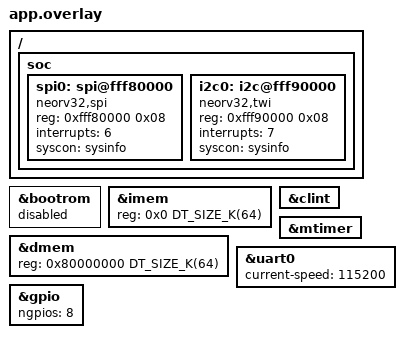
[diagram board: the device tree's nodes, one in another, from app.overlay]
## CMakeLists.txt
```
# Copyright (c) 2026
# SPDX-License-Identifier: GPL-3.0-or-later OR LicenseRef-Ostomachion-Commercial-1.0

cmake_minimum_required(VERSION 3.20.0)

list(APPEND ZEPHYR_EXTRA_MODULES ${CMAKE_CURRENT_SOURCE_DIR})

find_package(Zephyr REQUIRED HINTS $ENV{ZEPHYR_BASE})
project(ostomachion VERSION 0.1.0 LANGUAGES C CXX ASM)

target_include_directories(app PRIVATE include)

target_compile_options(app PRIVATE -Werror)

target_sources(app PRIVATE src/main.cpp)

# ZTest suites — only compiled when ZTEST is enabled
if(CONFIG_ZTEST)
  target_sources(app PRIVATE
    tests/test_spi.cpp
    tests/test_i2c.cpp
    tests/test_gpio.cpp
    # Hardware-independent filter-mask math: runs on the NEORV32 sim model.
    tests/test_filter_mask.cpp
  )
  if(CONFIG_WDT_NEORV32)
    target_sources(app PRIVATE tests/test_wdt.cpp)
  endif()
  if(CONFIG_FFT_ACCEL)
    target_sources(app PRIVATE tests/test_fft_accel.cpp)
  endif()
endif()

if(CONFIG_SHELL)
  target_sources(app PRIVATE src/test_runner.c)
  if(CONFIG_FFT_ACCEL)
    target_sources(app PRIVATE src/fft_shell.c)
  endif()
endif()

if(CONFIG_FFT_DEMO)
  target_sources(app PRIVATE src/fft_demo_main.c)
endif()
```

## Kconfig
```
# Ostomachion application-level Kconfig
# Copyright (c) 2026  SPDX-License-Identifier: GPL-3.0-or-later OR LicenseRef-Ostomachion-Commercial-1.0

menu "Ostomachion application"

config FFT_DEMO
	bool "Build the FFT accelerator host-pipe demo firmware"
	depends on FFT_ACCEL
	default n
	help
	  Enables compilation of src/fft_demo_main.c, which runs a dedicated
	  thread that drives the FFT accelerator from host-provided sample
	  frames carried over the FrontPanel BTPipe endpoints implemented by
	  fp_fft_pipe_bridge.vhd in xem7310_top.vhd.

	  The thread polls the bridge FIFO_IN at 0x90000000 for a full
	  4096-sample frame, runs fft_accel_transform(), and pushes the
	  result back through FIFO_OUT.  The HW cycle count is published
	  via the bridge's REG_PUBLISH register so the host PyQt demo
	  (tools/fft_demo/) can display the speed-up statistic.

	  This config has no effect unless the bitstream was built with the
	  fp_fft_pipe_bridge present (region 0x9000_0000 must respond to
	  XBUS accesses).

endmenu

source "Kconfig.zephyr"
```

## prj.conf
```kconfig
# Core Kernel Features
CONFIG_SERIAL=y
CONFIG_CONSOLE=y
CONFIG_UART_CONSOLE=y
CONFIG_UART_INTERRUPT_DRIVEN=n
CONFIG_GPIO=y
CONFIG_SPI=y
CONFIG_SPI_NEORV32=y
CONFIG_I2C=y
CONFIG_I2C_NEORV32=y

# Modern C++ Support
CONFIG_CPP=y
CONFIG_STD_CPP20=y
CONFIG_PICOLIBC=y

# NOTE: CONFIG_ZTEST is intentionally NOT set here.  prj.conf is the clean
# base/production config; the ZTEST framework is opt-in per build:
#   - GHDL sim test       : added by the `zephyr` Makefile target
#   - Twister / HW tests  : added via testcase.yaml extra_configs
# This keeps the CI firmware-analysis build (CONF_FILE=prj.conf) a real
# production image rather than a test build pulling in all tests/*.cpp.

# I2C slave address for the GHDL testbench slave model (0x50 = 80).
# Set to 0 to skip slave tests.
CONFIG_TEST_I2C_SLAVE_ADDR=80
```

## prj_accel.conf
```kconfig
# prj_accel.conf — Kconfig fragment for the automated ZTEST accelerator build
# Copyright (c) 2026  SPDX-License-Identifier: GPL-3.0-or-later OR LicenseRef-Ostomachion-Commercial-1.0
#
# Stacked on: prj.conf + prj_fpga.conf + prj_hw_test.conf
# Build mode: Automated / CI ZTEST accelerator build.
#
# This fragment only adds the FFT accelerator driver.  CONFIG_ZTEST is NOT set
# in prj.conf (the clean production base); it is supplied by the invoking layer
# — testcase.yaml extra_configs (CONFIG_ZTEST=y) for Twister/HW, or the
# `make test-accel-hw` target.  Verbose ZTEST output comes from prj_hw_test.conf.

CONFIG_FFT_ACCEL=y
CONFIG_FFT_ACCEL_LOG_LEVEL_INF=y
```

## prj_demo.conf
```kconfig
# prj_demo.conf — Kconfig fragment for the host-driven FFT demo firmware
# Copyright (c) 2026  SPDX-License-Identifier: GPL-3.0-or-later OR LicenseRef-Ostomachion-Commercial-1.0
#
# Stacked on: prj.conf + prj_fpga.conf + prj_accel.conf
# Build mode: standalone demo loop (no ZTEST, no Zephyr shell)
#
# Used by: `make demo-hw`.  Drives the FFT accelerator from sample frames
# pushed across the FrontPanel BTPipe endpoints 0x81 / 0xA1 (the host-side
# entry point lives in tools/fft_demo/).

# --- Disable ZTEST (the default base prj.conf enables it) ---
# CONFIG_ZTEST is not set

# --- Enable the application-level FFT demo thread ---
CONFIG_FFT_DEMO=y

# --- Larger stack for the demo thread + FFT transform ---
CONFIG_MAIN_STACK_SIZE=4096

# --- FPU on, matching prj_shell.conf (cosf in test helpers, future use) ---
CONFIG_FPU=y

# --- Logging surface (deferred so the LED-blink thread keeps the WDT fed) ---
CONFIG_LOG=y
CONFIG_LOG_MODE_DEFERRED=y
```

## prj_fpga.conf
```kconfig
# Ostomachion — FPGA (XEM7310-A200) Kconfig fragment
#
# Applied on top of prj.conf when building the FPGA firmware target.
# Increases stack sizes to suit a real RTOS workload and enables the
# interrupt-driven SPI/I2C driver paths (polling is retained in prj.conf
# for simulation convenience).

# Larger stacks for FPGA with real workloads
CONFIG_MAIN_STACK_SIZE=4096
CONFIG_SYSTEM_WORKQUEUE_STACK_SIZE=2048

# Interrupt-driven drivers — production hardware path
# (DTS nodes in app.overlay already declare the correct IRQ numbers;
# this just selects the IRQ code path inside the driver.)
CONFIG_SPI_NEORV32_INTERRUPT=y
CONFIG_I2C_NEORV32_INTERRUPT=y

# Watchdog — hardware WDT enabled (IO_WDT_EN=true in xem7310_top.vhd).
# The application feeds it every 500 ms in the LED blink thread.
# Default timeout: 5000 ms (5 s).  Increase if workloads block longer.
CONFIG_WATCHDOG=y
CONFIG_WDT_NEORV32=y
```

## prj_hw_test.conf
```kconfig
# Hardware test configuration overlay.
#
# Applied on top of prj.conf + prj_fpga.conf for hardware test builds:
#   make test-hw
#
# Enables verbose ztest output and per-subsystem logging so results can be
# read from the UART console at 115200 baud.
#
# CONFIG_TEST_I2C_SLAVE_ADDR=0 means the slave-dependent I2C tests are skipped
# gracefully.  Set to the 7-bit address of any attached I2C device to enable
# those tests (e.g. CONFIG_TEST_I2C_SLAVE_ADDR=80 for a device at 0x50).

# Zephyr logging subsystem
CONFIG_LOG=y
CONFIG_LOG_DEFAULT_LEVEL=3

# Per-driver log levels (INFO = level 3)
CONFIG_SPI_LOG_LEVEL_INF=y
CONFIG_I2C_LOG_LEVEL_INF=y
CONFIG_GPIO_LOG_LEVEL_INF=y

# Verbose ztest output — prints each test name and PASS/FAIL clearly
CONFIG_ZTEST_VERBOSE_OUTPUT=y

# Run the full I2C bus scan (111 probes, ~50 ms) — hardware only.
# Disabled by default to keep GHDL simulation within its 400 ms window.
CONFIG_TEST_I2C_BUS_SCAN=y

# Run the full 64-iteration SPI stress test — hardware only.
# Default (16) fits within the GHDL 400 ms window at ~1 ms/transfer.
CONFIG_TEST_SPI_STRESS_COUNT=64

# No I2C slave attached by default; override on the command line or in a
# per-board fragment if a slave device is present.
CONFIG_TEST_I2C_SLAVE_ADDR=0
```

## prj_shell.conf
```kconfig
# prj_shell.conf — Kconfig fragment for the interactive shell build
# Copyright (c) 2026  SPDX-License-Identifier: GPL-3.0-or-later OR LicenseRef-Ostomachion-Commercial-1.0
#
# Stacked on: prj.conf + prj_fpga.conf
# Build mode: Interactive / Development
#
# CONFIG_ZTEST is explicitly NOT set — the shell owns the UART terminal.
# The LED blink thread and shell thread run indefinitely after boot.

# --- Disable ZTEST (overrides any default) ---
# CONFIG_ZTEST is not set

# --- Zephyr shell ---
CONFIG_SHELL=y
CONFIG_SHELL_BACKEND_SERIAL=y
CONFIG_SHELL_CMD_BUFF_SIZE=128
CONFIG_SHELL_STACK_SIZE=2048
CONFIG_SHELL_LOG_BACKEND=y

# --- FFT accelerator driver ---
CONFIG_FFT_ACCEL=y

# --- Logging over shell ---
CONFIG_LOG=y
CONFIG_LOG_MODE_DEFERRED=y

# --- C++ support for fft_accel.hpp ---
CONFIG_CPP=y
CONFIG_STD_CPP20=y
CONFIG_FPU=y

# --- Larger stacks for shell + FFT workloads ---
CONFIG_MAIN_STACK_SIZE=4096
```

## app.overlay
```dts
#include <zephyr/dt-bindings/dt-util.h>

&bootrom {
	status = "disabled";
};

&imem {
	status = "okay";
	reg = <0x0 DT_SIZE_K(64)>;
};

&dmem {
	status = "okay";
	reg = <0x80000000 DT_SIZE_K(64)>;
};

&clint {
	status = "okay";
};

&mtimer {
	status = "okay";
};

&uart0 {
	status = "okay";
	current-speed = <115200>;
};

&gpio {
	status = "okay";
	ngpios = <8>;
};

/ {
	soc {
		spi0: spi@fff80000 {
			compatible = "neorv32,spi";
			reg = <0xfff80000 0x08>; /* two 32-bit registers: CTRL + DATA */
			status = "okay";
			interrupts = <6>;
			syscon = <&sysinfo>;
			#address-cells = <1>;
			#size-cells = <0>;
		};

		i2c0: i2c@fff90000 {
			compatible = "neorv32,twi";
			reg = <0xfff90000 0x08>; /* two 32-bit registers: CTRL + DCMD */
			status = "okay";
			interrupts = <7>;
			syscon = <&sysinfo>;
			#address-cells = <1>;
			#size-cells = <0>;
		};
	};
};
```

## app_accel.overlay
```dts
/* SPDX-License-Identifier: GPL-3.0-or-later OR LicenseRef-Ostomachion-Commercial-1.0 */
#include <zephyr/dt-bindings/dt-util.h>

/*
 * app_accel.overlay — DTS overlay for the AXI FFT accelerator pipeline
 * Copyright (c) 2026  SPDX-License-Identifier: GPL-3.0-or-later OR LicenseRef-Ostomachion-Commercial-1.0
 *
 * Applied in addition to app.overlay and app_fpga.overlay when building
 * the accelerator firmware (prj_accel.conf or prj_shell.conf).
 *
 * Address map (XBUS region 0x40000000–0x4FFFFFFF):
 *   0x40000000  AXI DMA control registers   128 B   (AXI4-Lite)
 *   0x40010000  AXI INTC                    128 B   (AXI4-Lite)
 *   0x40020000  AXI GPIO (xfft reset)       128 B   (AXI4-Lite)
 *   0x41000000  TX BRAM                      32 KB  (AXI4-Full)
 *   0x41008000  RX BRAM                      32 KB  (AXI4-Full)
 *
 * The FFT core is the Xilinx xfft IP instantiated in the block design.
 * It has no AXI4-Lite slave; it is driven purely via AXI4-Stream by the
 * AXI DMA and configured at synthesis time (forward, scale all stages).
 *
 * Interrupts (v1.1 — AXI INTC): three sources are aggregated by the AXI INTC
 * (Xilinx PG099) and OR-reduced onto the single NEORV32 MEI line (IRQ 11):
 *   INTC ch0 = AXI DMA mm2s_introut (MM2S complete / error)
 *   INTC ch1 = AXI DMA s2mm_introut (S2MM complete / error)
 *   INTC ch2 = xfft m_axis_status_tvalid (frame-done pulse; not overflow-only)
 * The driver ISR reads INTC ISR for definitive channel identification.  See
 * ACCEL_ARCH.md §2.2 and the `interrupts = <11>` property below.
 */

/ {
	soc {
		fft_accel: fft-accel@40000000 {
			compatible = "ostomachion,fft-accel";
			/* reg-names:  dma         tx_bram     rx_bram     intc        gpio        coeff_bram  */
			reg = <0x40000000 0x80>,
			      <0x41000000 0x8000>,
			      <0x41008000 0x8000>,
			      <0x40010000 0x80>,
			      <0x40020000 0x80>,
			      <0x42000000 0x4000>;
			/* coeff_bram (0x42000000, 16 KB): per-bin complex Q1.15 filter
			 * mask written by fft_accel_load_coeffs().  Present on the
			 * filter-pipeline bitstream (this overlay); the driver tolerates
			 * its absence on a forward-FFT-only build via DT_INST_REG_HAS_NAME. */
			reg-names = "dma", "tx_bram", "rx_bram", "intc", "gpio", "coeff_bram";
			/* dma-max-bytes is the runtime guard on RX (S2MM)
			 * transfer length.  A 4096-point transform uses exactly
			 * N × 4 = 16384 bytes (ACCEL_ARCH.md §4.4).  The value
			 * is 16384 + 4: one word of deliberate slack so the
			 * defense-in-depth `byte_len > dma-max-bytes` check
			 * (fft_accel.c) never trips on the only legal length,
			 * while still bounding a future variable-N path well
			 * below the 8192-word (32 KB) BRAM depth. */
			dma-max-bytes = <16388>;
			/* AXI INTC IRQ output → NEORV32 MEI line (INTC IRQ 11) */
			interrupts = <11>;
			interrupt-parent = <&intc>;
			status = "okay";
		};
	};
};

/* No XBUS DTS node required: the AXI peripherals are directly
 * memory-mapped in the NEORV32 address space and accessed via MMIO. */

/* The FFT driver + ZTEST suite exceeds 64 KB; increase IMEM to 128 KB.
 * The NEORV32 IMEM in the block design must be configured to match. */
&imem {
	reg = <0x0 DT_SIZE_K(128)>;
};
```

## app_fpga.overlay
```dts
#include <zephyr/dt-bindings/dt-util.h>

/* Ostomachion — FPGA (XEM7310-A200) DTS overlay
 *
 * Applied on top of app.overlay when building the FPGA firmware target.
 * The SPI/I2C MMIO addresses and interrupt numbers are identical between
 * simulation and FPGA; only the UART baud rate and hardware-specific
 * peripherals (WDT) differ.
 */

/* IMEM is 128 KiB on the production XEM7310 top (see fpga/xem7310/xem7310_top.vhd).
 * Keep app.overlay at 64 KiB for simulation; FPGA needs the full IMEM for
 * ZTEST + IRQ drivers + WDT (linker ROM must match hardware).
 */
&imem {
	reg = <0x0 DT_SIZE_K(128)>;
};

&uart0 {
	current-speed = <115200>;
};

/* ── Watchdog Timer ─────────────────────────────────────────────────────────
 * NEORV32 WDT is enabled via IO_WDT_EN=true in xem7310_top.vhd.
 * The Zephyr application feeds it via wdt_feed() in the LED blink thread.
 * clock-frequency must match CLOCK_FREQUENCY in xem7310_top.vhd (100 MHz).
 */
/ {
	soc {
		wdt0: watchdog@fffb0000 {
			compatible = "neorv32,wdt";
			reg = <0xfffb0000 0x8>;
			clock-frequency = <100000000>;
			status = "okay";
		};
	};
};
```

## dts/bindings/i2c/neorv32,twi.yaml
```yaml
# Copyright (c) 2026
# SPDX-License-Identifier: GPL-3.0-or-later OR LicenseRef-Ostomachion-Commercial-1.0

description: NEORV32 TWI (I2C-compatible) master controller

compatible: "neorv32,twi"

include:
  - i2c-controller.yaml
  - base.yaml

properties:
  reg:
    required: true

  interrupts:
    required: false

  syscon:
    type: phandle
    required: true
    description: phandle to NEORV32 SYSINFO syscon node.
```

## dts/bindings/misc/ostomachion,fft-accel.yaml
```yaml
# Copyright (c) 2026
# SPDX-License-Identifier: GPL-3.0-or-later OR LicenseRef-Ostomachion-Commercial-1.0
#
# DTS binding for the Ostomachion FFT accelerator pipeline.
# The FFT core is the Xilinx xfft IP; it has no AXI4-Lite slave interface.
# All data movement is handled by the AXI DMA.  Interrupt source
# identification is provided by the AXI INTC (Xilinx PG099).
# An AXI GPIO (Xilinx PG144) drives the xfft aresetn signal so the driver
# can flush the pipeline between transforms.
#
# Example DTS node:
#
#   fft_accel: fft-accel@40000000 {
#       compatible = "ostomachion,fft-accel";
#       reg = <0x40000000 0x80>,     /* AXI DMA control registers (128 B)  */
#             <0x41000000 0x8000>,   /* TX BRAM                   (32 KB)  */
#             <0x41008000 0x8000>,   /* RX BRAM                   (32 KB)  */
#             <0x40010000 0x80>,     /* AXI INTC (128 B AXI aperture)      */
#             <0x40020000 0x80>;     /* AXI GPIO (xfft reset, 128 B)       */
#       reg-names = "dma", "tx_bram", "rx_bram", "intc", "gpio";
#       dma-max-bytes = <16388>;
#       interrupts = <11>;          /* RISC-V MEI line (IRQ 11) */
#       status = "okay";
#   };

description: Ostomachion AXI DMA + Xilinx xfft + AXI INTC hardware accelerator pipeline

compatible: "ostomachion,fft-accel"

include: base.yaml

properties:
  reg:
    required: true

  reg-names:
    required: true
    description: |
      Must start with "dma", "tx_bram", "rx_bram", "intc", "gpio" in that order.
        dma     — AXI DMA control registers (128 B at 0x40000000)
        tx_bram — TX BRAM input buffer (32 KB at 0x41000000)
        rx_bram — RX BRAM output buffer (32 KB at 0x41008000)
        intc    — AXI INTC (128 B decode at 0x40010000; PG099 regs in low 32 B)
        gpio    — AXI GPIO (128 B at 0x40020000; ch1 bit0 = xfft aresetn,
                  ch1 bit1 = filter bypass; ch2 bit0/bit1 = overflow readback)

      OPTIONAL trailing entry (filter-pipeline bitstream only):
        coeff_bram — per-bin complex filter coefficient BRAM
                     (16 KB at 0x42000000; 4096 × {im,re} Q1.15).
      When absent the driver runs forward-FFT-only and
      fft_accel_load_coeffs() returns -ENOTSUP.

  dma-max-bytes:
    type: int
    required: true
    description: |
      Maximum DMA transfer length in bytes for one RX (S2MM) transfer.
      A 4096-point transform uses N * 4 = 16384 bytes (ACCEL_ARCH.md §4.4);
      this property is a runtime guard against an oversized transform —
      the driver rejects any transform whose required byte count exceeds
      this value.

  interrupts:
    required: true
    description: |
      Machine External Interrupt (MEI), IRQ 11 on the riscv,cpu-intc (&intc).

      Interrupt topology (AXI INTC, scalable multi-accelerator):
        INTC channel 0 = AXI DMA mm2s_introut  (MM2S completion / error)
        INTC channel 1 = AXI DMA s2mm_introut  (S2MM completion / error)
        INTC channel 2 = xfft m_axis_status_tvalid  (frame-complete pulse;
                         not overflow-only — see ACCEL_ARCH.md §2.2)
      The AXI INTC (PG099) OR-reduces pending channels into one MEI wire.
      The driver ISR reads INTC ISR (offset 0x00) for definitive channel
      identification, then acknowledges via INTC IAR (offset 0x0C).

      Expansion: add further accelerators by wiring their IRQs to INTC
      channels 3, 4, … and widening C_NUM_INTR_INPUTS in the block design.
      No firmware or DTS changes are required for the existing channels.
```

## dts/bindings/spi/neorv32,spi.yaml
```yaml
# Copyright (c) 2026
# SPDX-License-Identifier: GPL-3.0-or-later OR LicenseRef-Ostomachion-Commercial-1.0

description: NEORV32 SPI controller

compatible: "neorv32,spi"

include: [spi-controller.yaml, base.yaml]

properties:
  reg:
    required: true

  interrupts:
    required: false

  syscon:
    type: phandle
    required: true
    description: phandle to NEORV32 SYSINFO syscon node.
```

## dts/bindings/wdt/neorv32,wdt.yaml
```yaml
# Copyright (c) 2026
# SPDX-License-Identifier: GPL-3.0-or-later OR LicenseRef-Ostomachion-Commercial-1.0
#
# DTS binding for the NEORV32 Watchdog Timer (WDT).
#
# The NEORV32 WDT generates a system hardware reset when the 24-bit timeout
# counter reaches the programmed threshold value.  The counter increments at
# CLK/4096.  No interrupt is generated (reset only); this binding therefore
# does not declare an 'interrupts' property.
#
# Password: write 0x709D1AB3 to the RESET register to feed the watchdog.
#
# Register map (from neorv32_wdt.h):
#   0x00 CTRL   r/w  bit[0]=EN, bit[1]=LOCK, bit[2]=STRICT,
#                    bits[4:3]=RCAUSE (r/-), bits[31:8]=TIMEOUT
#   0x04 RESET  -/w  write WDT_PASSWORD (0x709D1AB3) to feed
#
# Example DTS node (in app_fpga.overlay):
#
#   wdt0: watchdog@fffb0000 {
#       compatible = "neorv32,wdt";
#       reg = <0xfffb0000 0x8>;
#       clock-frequency = <100000000>;
#       status = "okay";
#   };

description: NEORV32 hardware watchdog timer (reset-only)

compatible: "neorv32,wdt"

include: base.yaml

properties:
  reg:
    required: true

  clock-frequency:
    type: int
    required: true
    description: |
      System clock frequency in Hz.  Used to convert the requested timeout
      in milliseconds to the 24-bit TIMEOUT counter value.
      Timeout counter increments at clock-frequency / 4096.
      Maximum timeout = 0xFFFFFF * 4096 / clock-frequency seconds.
```

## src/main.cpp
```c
// Copyright (c) 2026
// SPDX-License-Identifier: GPL-3.0-or-later OR LicenseRef-Ostomachion-Commercial-1.0
//
// Ostomachion — application entry point.
//
// Architecture overview:
//   - The ztest framework (CONFIG_ZTEST=y) provides its own main() that
//     discovers and runs all registered ZTEST_SUITE instances under tests/
//     before returning: test_spi, test_i2c, test_gpio, plus test_wdt
//     (CONFIG_WDT_NEORV32) and test_fft_accel (CONFIG_FFT_ACCEL) — see
//     CMakeLists.txt for the gating.
//   - A SYS_INIT hook sets GPIO pin 0 (LED0) high early in the boot sequence.
//     This gives the simulation testbench an immediate proof-of-life signal
//     (gpio_toggle_cnt increments from 0→1) before the polling test drivers
//     monopolise the CPU.
//   - The led_blink thread provides a visible heartbeat on real hardware once
//     the tests have completed and the scheduler has idle time.
//   - When CONFIG_WDT_NEORV32=y (FPGA target), the led_blink thread also feeds
//     the hardware watchdog every 500 ms.  The WDT timeout is 5 s by default
//     (configured in wdt_setup_fpga); if the LED thread hangs for more than
//     5 s the system resets automatically.
//
// To add a new test suite: create tests/test_<peripheral>.cpp, register it
// with ZTEST_SUITE, and add it to CMakeLists.txt target_sources().

#include <zephyr/devicetree.h>
#include <zephyr/drivers/gpio.h>
#include <zephyr/init.h>
#include <zephyr/kernel.h>

#ifdef CONFIG_WDT_NEORV32
#include <zephyr/drivers/watchdog.h>
#endif

#include "ostomachion/hal/gpio.hpp"

// Runs after driver init, before the main thread.  Drives LED0 / gpio[0] high
// so that the testbench watchdog sees at least one GPIO transition within its
// 190 ms check window even when polling drivers hold the CPU throughout tests.
static int gpio_alive_init(void)
{
    const struct gpio_dt_spec led = GPIO_DT_SPEC_GET(DT_ALIAS(led0), gpios);
    if (!device_is_ready(led.port)) {
        return 0;
    }
    gpio_pin_configure_dt(&led, GPIO_OUTPUT_ACTIVE);
    gpio_pin_set_dt(&led, 1); // 0->1 transition detected by testbench watchdog
    return 0;
}
SYS_INIT(gpio_alive_init, APPLICATION, 0);

#ifdef CONFIG_WDT_NEORV32
// WDT channel ID returned by wdt_install_timeout(); stored for wdt_feed().
static int g_wdt_channel_id = -1;

// Initialise the hardware watchdog with a 5-second timeout.
// Called from led_blink_thread before the blink loop starts so that the
// WDT is only armed once the system has fully booted.
static void wdt_setup_fpga(const struct device *wdt_dev)
{
    if (!device_is_ready(wdt_dev)) {
        return;
    }

    static const struct wdt_timeout_cfg wdt_cfg = {
        .window =
            {
                .min = 0U,
                .max = 5000U, // 5 s timeout; LED thread feeds every 500 ms
            },
        .callback = NULL, // reset-only mode
        .flags    = 0U,
    };

    g_wdt_channel_id = wdt_install_timeout(wdt_dev, &wdt_cfg);
    if (g_wdt_channel_id < 0) {
        return;
    }

    wdt_setup(wdt_dev, WDT_OPT_PAUSE_HALTED_BY_DBG);
}
#endif // CONFIG_WDT_NEORV32

static void led_blink_thread(void *, void *, void *)
{
    ostomachion::hal::GpioOutput led{GPIO_DT_SPEC_GET(DT_ALIAS(led0), gpios)};

#ifdef CONFIG_WDT_NEORV32
    const struct device *wdt_dev = DEVICE_DT_GET_OR_NULL(DT_NODELABEL(wdt0));
    wdt_setup_fpga(wdt_dev);
#endif

    while (true) {
        led.toggle();
        k_msleep(500);

#ifdef CONFIG_WDT_NEORV32
        if ((wdt_dev != NULL) && (g_wdt_channel_id >= 0)) {
            wdt_feed(wdt_dev, g_wdt_channel_id);
        }
#endif
    }
}

K_THREAD_DEFINE(led_blink, 1536, led_blink_thread,
                NULL, NULL, NULL, 7, 0, 0);
```

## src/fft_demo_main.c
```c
/*
 * fft_demo_main.c — Realtime FFT-accelerator demo driver thread
 * Copyright (c) 2026  SPDX-License-Identifier: GPL-3.0-or-later OR LicenseRef-Ostomachion-Commercial-1.0
 *
 * Compiled when CONFIG_FFT_DEMO=y (see zephyr_app/Kconfig + prj_demo.conf).
 *
 * Drives the existing FFT hardware accelerator (Xilinx xfft via AXI DMA)
 * from sample frames pushed across the FrontPanel BTPipe endpoints that
 * the fp_fft_pipe_bridge.vhd RTL module exposes at XBUS region
 * 0x9000_0000.  The CPU stays in the loop: it MMIO-copies each input
 * frame from FIFO_IN into TX BRAM (inside the HAL via fft_accel_transform),
 * runs the transform, and MMIO-copies the result from the driver's output
 * buffer into FIFO_OUT.
 *
 * MMIO register window (matches fp_fft_pipe_bridge.vhd — 32-byte window):
 *   0x9000_0000 (R) — pop one 32-bit sample from FIFO_IN
 *   0x9000_0004 (W) — push one 32-bit sample to FIFO_OUT
 *   0x9000_0008 (R) — status = {fifo_out_count[15:0], fifo_in_count[15:0]}
 *   0x9000_000C (W) — store HW FFT cycle count + bump frame counter
 *   0x9000_0010 (R) — filter control word from the host (WireIn 0x01)
 *   0x9000_0014 (W) — filter status echo to the host (WireOut 0x28)
 *
 * Each FIFO sample is packed identically to the TX/RX BRAMs the HAL talks
 * to: bits[15:0] = re (Q1.15), bits[31:16] = im (Q1.15).
 *
 * Host-programmable spectral filter:
 *   The host selects a brick-wall filter (LP/HP/BP/notch) by writing a control
 *   word to WireIn 0x01, which this thread reads at 0x9000_0010.  On a confirmed
 *   change the thread synthesises the per-bin complex mask and loads it into the
 *   coeff BRAM (fft_accel_load_coeffs), then runs fft_accel_transform_filtered
 *   instead of the plain forward FFT — so the output frame is the FILTERED
 *   TIME-DOMAIN signal (inverse transform of H[k]·X[k]) rather than frequency
 *   bins.  The thread echoes the applied mode / availability / overflow back to
 *   the host on WireOut 0x28 so the host knows how to interpret the frame.
 *
 *   Control word (0x9000_0010):
 *     [2:0]   mode  (0=bypass/off, 1=LP, 2=HP, 3=BP, 4=notch)
 *     [14:3]  lo    (folded-frequency bin, 0..2048)
 *     [26:15] hi    (folded-frequency bin, 0..2048)
 *   Status word (0x9000_0014):
 *     [2:0] applied_mode  [3] filter_avail  [4] last_overflow  [5] last_failed
 *
 * Frame flow per iteration:
 *   1. Wait for FIFO_IN to hold a full frame (4096 samples).
 *   2. Pop the 4096 samples into a local Q1.15 complex buffer.
 *   3. Read + debounce the filter control word; on a confirmed change, reload
 *      the coeff BRAM (mode!=bypass) and record availability.
 *   4. Run the selected transform (forward FFT, or FFT→filter→IFFT) and measure
 *      HW cycles.
 *   5. Wait for the host to have drained the previous frame from
 *      FIFO_OUT (status.out_count == 0).
 *   6. Publish HW cycles to WireOut 0x25 + bump the frame counter (WireOut 0x26)
 *      and write the filter status echo to WireOut 0x28.
 *   7. Push the 4096 output samples to FIFO_OUT for the host.
 *
 * The host polls fifo_out_count >= 4096 to know when to read the frame.
 * Because step 6 runs before step 7, the cycles + status registers are
 * guaranteed fresh by the time the host sees the count rise.
 */

#include <zephyr/kernel.h>
#include <zephyr/device.h>
#include <zephyr/devicetree.h>
#include <zephyr/logging/log.h>
#include <zephyr/sys/sys_io.h>

#include <zephyr/drivers/misc/fft_accel.h>

#include <stdint.h>

LOG_MODULE_REGISTER(fft_demo, LOG_LEVEL_INF);

#define FFT_N             4096

/* FrontPanel FFT pipe bridge MMIO map (xem7310_top.vhd region 0x9000_0000) */
#define FFT_PIPE_BASE        0x90000000UL
#define FFT_PIPE_POP         (FFT_PIPE_BASE + 0x0)   /* R: pop one sample      */
#define FFT_PIPE_PUSH        (FFT_PIPE_BASE + 0x4)   /* W: push one sample     */
#define FFT_PIPE_STATUS      (FFT_PIPE_BASE + 0x8)   /* R: fifo counts         */
#define FFT_PIPE_PUBLISH     (FFT_PIPE_BASE + 0xC)   /* W: cycles + frame bump */
#define FFT_PIPE_FILTER_CFG  (FFT_PIPE_BASE + 0x10)  /* R: host filter cfg word */
#define FFT_PIPE_APPLIED     (FFT_PIPE_BASE + 0x14)  /* W: filter status echo   */

#define STATUS_IN_COUNT(s)   ((uint32_t)((s) & 0xFFFFU))
#define STATUS_OUT_COUNT(s)  ((uint32_t)(((s) >> 16) & 0xFFFFU))

/* Filter control word (FFT_PIPE_FILTER_CFG) field accessors. */
#define CFG_MODE(c)          ((uint32_t)((c) & 0x7U))
#define CFG_LO(c)            ((uint32_t)(((c) >> 3) & 0xFFFU))
#define CFG_HI(c)            ((uint32_t)(((c) >> 15) & 0xFFFU))

/* Filter modes (must match the host control-word encoding). */
#define FILT_BYPASS  0U
#define FILT_LP      1U
#define FILT_HP      2U
#define FILT_BP      3U
#define FILT_NOTCH   4U

/* Filter status word (FFT_PIPE_APPLIED) bit fields. */
#define STAT_AVAIL     BIT(3)
#define STAT_OVERFLOW  BIT(4)
#define STAT_FAILED    BIT(5)

/* Shared sample buffers — kept at file scope to avoid 32 KB on the stack. */
static struct fft_sample_t g_demo_in[FFT_N];
static struct fft_sample_t g_demo_out[FFT_N];

static inline uint32_t cycles_to_us(uint32_t cycles)
{
#if CONFIG_SYS_CLOCK_HW_CYCLES_PER_SEC > 0
	return (uint32_t)((uint64_t)cycles * 1000000U /
			  CONFIG_SYS_CLOCK_HW_CYCLES_PER_SEC);
#else
	return cycles;
#endif
}

/* Folded (physical) frequency index — matches filter_mask.hpp folded_freq()
 * and fft_shell.c folded_freq_sh().  Bin k mirrors to N-k; the lower of the two
 * is the physical frequency, giving Hermitian-symmetric masks. */
static inline int demo_folded_freq(int k, int n)
{
	int mirror = n - k;
	return (k <= mirror) ? k : mirror;
}

/* Synthesise a brick-wall mask for `mode` (lo/hi folded-bin edges) into out[].
 * Bit-for-bit identical to fft_shell.c's cmd_fft_filter loop and to the host's
 * synth_mask() so the on-screen H[k] overlay matches the fabric exactly.
 * Passband bins get { 0x7FFF, 0 }; stopband bins { 0, 0 }. */
static void demo_synth_mask(uint32_t mode, int lo, int hi,
			    struct fft_sample_t *out)
{
	for (int k = 0; k < FFT_N; k++) {
		int f = demo_folded_freq(k, FFT_N);
		bool pass;
		switch (mode) {
		case FILT_LP:    pass = (f <= hi);            break;
		case FILT_HP:    pass = (f >= lo);            break;
		case FILT_BP:    pass = (f >= lo && f <= hi); break;
		case FILT_NOTCH: pass = (f < lo  || f > hi);  break;
		default:         pass = false;                break;
		}
		out[k].re = pass ? (int16_t)0x7FFF : (int16_t)0;
		out[k].im = 0;
	}
}

static void fft_demo_thread(void *p1, void *p2, void *p3)
{
	ARG_UNUSED(p1);
	ARG_UNUSED(p2);
	ARG_UNUSED(p3);

	const struct device *dev = DEVICE_DT_GET(DT_NODELABEL(fft_accel));
	if (!device_is_ready(dev)) {
		LOG_ERR("fft_accel not ready — check DTS overlay and that the "
			"accelerator bitstream is loaded");
		return;
	}

	LOG_INF("FFT demo loop ready (N=%d, pipe @ 0x%08lx)",
		FFT_N, (unsigned long)FFT_PIPE_BASE);

	uint32_t frame_n = 0;
	/* Filter state.  applied_cfg starts at all-ones (never a valid cfg word —
	 * mode field 0x7 is unused) so the first real cfg, including a host's
	 * explicit "bypass" at startup, always counts as a change and is acted on.
	 * filter_avail tracks whether this bitstream actually has the coeff BRAM
	 * (load_coeffs returns -ENOTSUP on a forward-FFT-only build). */
	uint32_t applied_cfg = 0xFFFFFFFFU;
	uint32_t applied_mode = FILT_BYPASS;
	bool filter_avail = true;

	while (true) {
		/* 1. Wait for a complete input frame in FIFO_IN. */
		uint32_t status;
		do {
			status = sys_read32(FFT_PIPE_STATUS);
			if (STATUS_IN_COUNT(status) < FFT_N) {
				k_msleep(1);
			}
		} while (STATUS_IN_COUNT(status) < FFT_N);

		/* 2. Pop the frame from FIFO_IN.  Each 32-bit word carries
		 *    {im[15:0], re[15:0]} — the same packing the HAL uses
		 *    when writing TX BRAM (ACCEL_ARCH.md §3 step 2). */
		for (int i = 0; i < FFT_N; i++) {
			uint32_t w = sys_read32(FFT_PIPE_POP);
			g_demo_in[i].re = (int16_t)(w & 0xFFFFU);
			g_demo_in[i].im = (int16_t)((w >> 16) & 0xFFFFU);
		}

		/* 3. Read + debounce the host filter control word.  The host's
		 *    UpdateWireIns can momentarily tear the multi-field word, so we
		 *    require two reads (straddling the frame pop above, which gives
		 *    them ample separation) to agree before acting — and only when the
		 *    confirmed value differs from what we last applied.  On a confirmed
		 *    change with a non-bypass mode we synthesise the brick-wall mask
		 *    into g_demo_out and load it into the coeff BRAM.
		 *
		 *    Reusing g_demo_out as the coeff scratch is safe ONLY because
		 *    fft_accel_load_coeffs() is synchronous: it copies the table into
		 *    fabric BRAM and fences before returning, and the previous frame's
		 *    output was already pushed to FIFO_OUT last iteration.  The
		 *    transform in step 4 then overwrites g_demo_out.  If coeff loading
		 *    ever became async/DMA-backed, this reuse would break — use a
		 *    dedicated buffer then (DMEM permitting). */
		uint32_t cfg_a = sys_read32(FFT_PIPE_FILTER_CFG);
		uint32_t cfg_b = sys_read32(FFT_PIPE_FILTER_CFG);
		if (cfg_a == cfg_b && cfg_a != applied_cfg) {
			uint32_t mode = CFG_MODE(cfg_a);
			if (mode != FILT_BYPASS) {
				demo_synth_mask(mode, (int)CFG_LO(cfg_a),
						(int)CFG_HI(cfg_a), g_demo_out);
				int lrc = fft_accel_load_coeffs(dev, g_demo_out, FFT_N);
				if (lrc == -ENOTSUP) {
					/* Forward-FFT-only bitstream: no coeff BRAM.
					 * Fall back to plain FFT and tell the host the
					 * filter datapath is unavailable. */
					filter_avail = false;
					applied_mode = FILT_BYPASS;
				} else if (lrc != 0) {
					LOG_ERR("frame %u: load_coeffs failed: %d",
						frame_n, lrc);
					filter_avail = true;
					applied_mode = FILT_BYPASS;
				} else {
					filter_avail = true;
					applied_mode = mode;
				}
			} else {
				applied_mode = FILT_BYPASS;
			}
			applied_cfg = cfg_a;
			LOG_INF("filter cfg=0x%08x → mode=%u avail=%d",
				cfg_a, applied_mode, (int)filter_avail);
		}

		/* 4. Run the selected transform and measure compute cycles only.
		 *    Bypass / unavailable-filter → forward FFT (frequency bins);
		 *    otherwise FFT → filter → IFFT (filtered TIME-DOMAIN output). */
		bool filtered = (applied_mode != FILT_BYPASS) && filter_avail;
		uint32_t t0 = k_cycle_get_32();
		int rc = filtered
			? fft_accel_transform_filtered(dev, g_demo_in, g_demo_out, FFT_N)
			: fft_accel_transform(dev, g_demo_in, g_demo_out, FFT_N);
		uint32_t t1 = k_cycle_get_32();

		if (rc != 0) {
			LOG_ERR("frame %u: transform failed: %d", frame_n, rc);
			/* Tell the host this frame failed (status echo) and bump the
			 * frame counter with a zero-cycles sentinel so it sees forward
			 * progress without reading stale output. */
			uint32_t st = applied_mode
				    | (filter_avail ? STAT_AVAIL : 0U)
				    | STAT_FAILED;
			sys_write32(st, FFT_PIPE_APPLIED);
			sys_write32(0, FFT_PIPE_PUBLISH);
			continue;
		}

		uint32_t hw_cycles = t1 - t0;
		bool overflow = fft_accel_get_last_overflow(dev);

		/* 5. Wait until the host has consumed any prior output frame.
		 *    On the first iteration FIFO_OUT is empty, so this returns
		 *    immediately. */
		while (STATUS_OUT_COUNT(sys_read32(FFT_PIPE_STATUS)) != 0) {
			k_msleep(1);
		}

		/* 6. Publish HW cycles + filter status BEFORE pushing samples so the
		 *    host reads fresh values when fifo_out_count rises to FFT_N.  The
		 *    status echo lets the host interpret the frame correctly (freq bins
		 *    vs filtered time samples) and surface overflow. */
		uint32_t st = applied_mode
			    | (filter_avail ? STAT_AVAIL : 0U)
			    | (overflow ? STAT_OVERFLOW : 0U);
		sys_write32(st, FFT_PIPE_APPLIED);
		sys_write32(hw_cycles, FFT_PIPE_PUBLISH);

		/* 7. Push the result to FIFO_OUT.  Same {im, re} packing. */
		for (int i = 0; i < FFT_N; i++) {
			uint32_t w = ((uint32_t)(uint16_t)g_demo_out[i].im << 16)
				   |  (uint32_t)(uint16_t)g_demo_out[i].re;
			sys_write32(w, FFT_PIPE_PUSH);
		}

		frame_n++;
		if ((frame_n & 0x1FU) == 0U) {
			LOG_INF("frames=%u  hw=%u cycles (%u us)  mode=%u%s",
				frame_n, hw_cycles, cycles_to_us(hw_cycles),
				applied_mode, overflow ? " OVF" : "");
		}
	}
}

K_THREAD_DEFINE(fft_demo_tid, 4096, fft_demo_thread,
		NULL, NULL, NULL, 5, 0, 0);
```

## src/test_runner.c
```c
/*
 * test_runner.c — Zephyr shell "test" command
 * Copyright (c) 2026  SPDX-License-Identifier: GPL-3.0-or-later OR LicenseRef-Ostomachion-Commercial-1.0
 *
 * Interactive test runner for the development / shell firmware image
 * (prj_shell.conf).  Tests are standalone functions — no ZTEST macros —
 * so they can be invoked individually from the shell prompt.
 *
 * Shell session examples:
 *   uart:~$ test run spi
 *   [TEST] loopback_boundary ... PASS
 *   [TEST] multibyte_loopback ... PASS
 *   [TEST] stress_16           ... PASS
 *   [TEST] spi: 3 passed, 0 failed
 *
 *   uart:~$ test run all
 *   [TEST] spi: 3/3  i2c: 2/2  gpio: 2/2  fft: 2/2
 */

#include <zephyr/kernel.h>
#include <zephyr/shell/shell.h>
#include <zephyr/device.h>
#include <zephyr/devicetree.h>
#include <zephyr/drivers/spi.h>
#include <zephyr/drivers/i2c.h>
#include <zephyr/drivers/gpio.h>
#include <zephyr/sys/sys_io.h>
#if defined(CONFIG_FFT_ACCEL)
#include <zephyr/drivers/misc/fft_accel.h>
#endif

#include <string.h>
#include <stdint.h>
#include <math.h>

/* ── Result tracking helpers ─────────────────────────────────────────────── */

struct test_result {
	int passed;
	int failed;
};

#define TEST_RUN(sh, res, name, fn)                                \
	do {                                                           \
		int _rc = (fn);                                            \
		if (_rc == 0) {                                            \
			(res)->passed++;                                       \
			shell_print(sh, "[TEST] %-28s PASS", (name));         \
		} else {                                                   \
			(res)->failed++;                                       \
			shell_print(sh, "[TEST] %-28s FAIL (err %d)",         \
				    (name), _rc);                                  \
		}                                                          \
	} while (0)

/* ── SPI tests ───────────────────────────────────────────────────────────── */

static int spi_test_loopback_boundary(void)
{
	const struct device *dev = DEVICE_DT_GET(DT_NODELABEL(spi0));
	if (!device_is_ready(dev)) {
		return -ENODEV;
	}

	static const struct spi_config cfg = {
		.frequency = 1000000,
		.operation = SPI_OP_MODE_MASTER | SPI_WORD_SET(8) |
			     SPI_TRANSFER_MSB,
	};

	uint8_t tx_buf[2] = {0x00, 0xFF};
	uint8_t rx_buf[2] = {0x55, 0x55};
	struct spi_buf tx = {.buf = tx_buf, .len = 2};
	struct spi_buf rx = {.buf = rx_buf, .len = 2};
	struct spi_buf_set txs = {.buffers = &tx, .count = 1};
	struct spi_buf_set rxs = {.buffers = &rx, .count = 1};

	int rc = spi_transceive(dev, &cfg, &txs, &rxs);
	if (rc != 0) {
		return rc;
	}
	/* In loopback: rx should mirror tx */
	return (rx_buf[0] == 0x00 && rx_buf[1] == 0xFF) ? 0 : -EIO;
}

static int spi_test_multibyte(void)
{
	const struct device *dev = DEVICE_DT_GET(DT_NODELABEL(spi0));
	if (!device_is_ready(dev)) {
		return -ENODEV;
	}

	static const struct spi_config cfg = {
		.frequency = 1000000,
		.operation = SPI_OP_MODE_MASTER | SPI_WORD_SET(8) |
			     SPI_TRANSFER_MSB,
	};

	uint8_t tx_buf[8] = {0x01, 0x02, 0x03, 0x04, 0x05, 0x06, 0x07, 0x08};
	uint8_t rx_buf[8];
	struct spi_buf tx = {.buf = tx_buf, .len = 8};
	struct spi_buf rx = {.buf = rx_buf, .len = 8};
	struct spi_buf_set txs = {.buffers = &tx, .count = 1};
	struct spi_buf_set rxs = {.buffers = &rx, .count = 1};

	int rc = spi_transceive(dev, &cfg, &txs, &rxs);
	if (rc != 0) {
		return rc;
	}
	return (memcmp(tx_buf, rx_buf, 8) == 0) ? 0 : -EIO;
}

static int spi_test_stress(void)
{
	const struct device *dev = DEVICE_DT_GET(DT_NODELABEL(spi0));
	if (!device_is_ready(dev)) {
		return -ENODEV;
	}

	static const struct spi_config cfg = {
		.frequency = 1000000,
		.operation = SPI_OP_MODE_MASTER | SPI_WORD_SET(8) |
			     SPI_TRANSFER_MSB,
	};

	for (int i = 0; i < 16; i++) {
		uint8_t tx_buf = (uint8_t)i;
		uint8_t rx_buf = 0x55;
		struct spi_buf tx = {.buf = &tx_buf, .len = 1};
		struct spi_buf rx = {.buf = &rx_buf, .len = 1};
		struct spi_buf_set txs = {.buffers = &tx, .count = 1};
		struct spi_buf_set rxs = {.buffers = &rx, .count = 1};

		int rc = spi_transceive(dev, &cfg, &txs, &rxs);
		if (rc != 0 || rx_buf != tx_buf) {
			return -EIO;
		}
	}
	return 0;
}

/* ── I2C tests ───────────────────────────────────────────────────────────── */

static int i2c_test_no_ack(void)
{
	const struct device *dev = DEVICE_DT_GET(DT_NODELABEL(i2c0));
	if (!device_is_ready(dev)) {
		return -ENODEV;
	}
	/* Address 0x7F is reserved / typically unpopulated — expect slave NACK.
	 * The driver reports -ENXIO on address-phase NACK (aligned with ZTEST
	 * test_nack_nonexistent which asserts exactly -ENXIO). */
	uint8_t buf = 0;
	int rc = i2c_write(dev, &buf, 1, 0x7F);
	return (rc == -ENXIO) ? 0 : -EBADE;
}

static int i2c_test_nack_recovery(void)
{
	const struct device *dev = DEVICE_DT_GET(DT_NODELABEL(i2c0));
	if (!device_is_ready(dev)) {
		return -ENODEV;
	}
	uint8_t buf = 0;
	/* Five consecutive NACKs — matches ZTEST test_nack_repeated coverage.
	 * Each attempt must return -ENXIO; the driver must not corrupt state. */
	for (int i = 0; i < 5; i++) {
		int rc = i2c_write(dev, &buf, 1, 0x7F);
		if (rc != -ENXIO) {
			return -EBADE;
		}
	}
	return 0;
}

/* ── GPIO / LED tests ─────────────────────────────────────────────────────── */

static const struct gpio_dt_spec k_leds[] = {
	GPIO_DT_SPEC_GET(DT_ALIAS(led0), gpios),
	GPIO_DT_SPEC_GET(DT_ALIAS(led1), gpios),
	GPIO_DT_SPEC_GET(DT_ALIAS(led2), gpios),
	GPIO_DT_SPEC_GET(DT_ALIAS(led3), gpios),
};

static int gpio_test_configure(void)
{
	for (int i = 0; i < ARRAY_SIZE(k_leds); i++) {
		if (!gpio_is_ready_dt(&k_leds[i])) {
			return -ENODEV;
		}
		int rc = gpio_pin_configure_dt(&k_leds[i], GPIO_OUTPUT_INACTIVE);
		if (rc != 0) {
			return rc;
		}
	}
	return 0;
}

static int gpio_test_set_clear(void)
{
	for (int i = 0; i < ARRAY_SIZE(k_leds); i++) {
		int rc = gpio_pin_set_dt(&k_leds[i], 1);
		if (rc != 0) {
			return rc;
		}
	}
	for (int i = 0; i < ARRAY_SIZE(k_leds); i++) {
		int rc = gpio_pin_set_dt(&k_leds[i], 0);
		if (rc != 0) {
			return rc;
		}
	}
	return 0;
}

/* ── FFT tests (shell path) ──────────────────────────────────────────────── */

#if defined(CONFIG_FFT_ACCEL)

/* int64_t avoids overflow when re = im = INT16_MIN: (int32_t)(-32768)^2 * 2
 * would overflow int32_t. */
static int64_t _mag_sq(int16_t re, int16_t im)
{
	return (int64_t)re * re + (int64_t)im * im;
}

#define FFT_N 4096

/* Reuse the buffers already allocated in fft_shell.c to avoid a second
 * 32 KB BSS footprint for the same shell firmware image. */
extern struct fft_sample_t g_fft_in[FFT_N];
extern struct fft_sample_t g_fft_out[FFT_N];

static int fft_test_dc_response(void)
{
	const struct device *dev = DEVICE_DT_GET(DT_NODELABEL(fft_accel));
	if (!device_is_ready(dev)) {
		return -ENODEV;
	}

	for (int i = 0; i < FFT_N; i++) {
		g_fft_in[i].re = 16384;
		g_fft_in[i].im = 0;
	}

	int rc = fft_accel_transform(dev, g_fft_in, g_fft_out, FFT_N);
	if (rc != 0) {
		return rc;
	}

	int64_t bin0 = _mag_sq(g_fft_out[0].re, g_fft_out[0].im);
	for (int k = 1; k < FFT_N; k++) {
		if (_mag_sq(g_fft_out[k].re, g_fft_out[k].im) >= bin0) {
			return -EIO;
		}
	}
	return 0;
}

static int fft_test_single_tone(void)
{
	const struct device *dev = DEVICE_DT_GET(DT_NODELABEL(fft_accel));
	if (!device_is_ready(dev)) {
		return -ENODEV;
	}

	/* Real cosine at bin 8: x[k] = 0.5 * cos(2π·8·k/4096), im = 0.
	 * A real cosine produces symmetric peaks at bin 8 AND its mirror
	 * bin 4088 (= 4096 - 8); the peak detector must accept either. */
	const int target = 8;
	for (int k = 0; k < FFT_N; k++) {
		float angle = 2.0f * 3.14159265f * (float)target * k / (float)FFT_N;
		g_fft_in[k].re = (int16_t)(16384.0f * cosf(angle));
		g_fft_in[k].im = 0;
	}

	int rc = fft_accel_transform(dev, g_fft_in, g_fft_out, FFT_N);
	if (rc != 0) {
		return rc;
	}

	int peak_bin = 0;
	int64_t peak = 0;
	for (int k = 0; k < FFT_N; k++) {
		int64_t m = _mag_sq(g_fft_out[k].re, g_fft_out[k].im);
		if (m > peak) {
			peak = m;
			peak_bin = k;
		}
	}
	/* Accept bin 8 (±1) or its mirror bin 4088 (±1) */
	bool ok = ((peak_bin >= 7 && peak_bin <= 9) ||
		   (peak_bin >= 4087 && peak_bin <= 4089));
	return ok ? 0 : -EIO;
}

#endif /* CONFIG_FFT_ACCEL */

/* ── Suite runners ───────────────────────────────────────────────────────── */

static void run_spi(const struct shell *sh, struct test_result *r)
{
	TEST_RUN(sh, r, "spi_loopback_boundary", spi_test_loopback_boundary());
	TEST_RUN(sh, r, "spi_multibyte_loopback", spi_test_multibyte());
	TEST_RUN(sh, r, "spi_stress_16",          spi_test_stress());
	shell_print(sh, "[TEST] spi: %d passed, %d failed", r->passed, r->failed);
}

static void run_i2c(const struct shell *sh, struct test_result *r)
{
	TEST_RUN(sh, r, "i2c_no_ack",            i2c_test_no_ack());
	TEST_RUN(sh, r, "i2c_nack_recovery",     i2c_test_nack_recovery());
	shell_print(sh, "[TEST] i2c: %d passed, %d failed", r->passed, r->failed);
}

static void run_gpio(const struct shell *sh, struct test_result *r)
{
	TEST_RUN(sh, r, "gpio_configure",  gpio_test_configure());
	TEST_RUN(sh, r, "gpio_set_clear",  gpio_test_set_clear());
	shell_print(sh, "[TEST] gpio: %d passed, %d failed", r->passed, r->failed);
}

#if defined(CONFIG_FFT_ACCEL)
static void run_fft(const struct shell *sh, struct test_result *r)
{
	TEST_RUN(sh, r, "fft_dc_response",   fft_test_dc_response());
	TEST_RUN(sh, r, "fft_single_tone",   fft_test_single_tone());
	shell_print(sh, "[TEST] fft: %d passed, %d failed", r->passed, r->failed);
}
#endif /* CONFIG_FFT_ACCEL */

/* ── Shell command handlers ──────────────────────────────────────────────── */

static int cmd_test_run(const struct shell *sh, size_t argc, char **argv)
{
	if (argc < 2) {
#if defined(CONFIG_FFT_ACCEL)
		shell_print(sh, "Usage: test run [spi|i2c|gpio|fft|all]");
#else
		shell_print(sh, "Usage: test run [spi|i2c|gpio|all]");
#endif
		return -EINVAL;
	}

	struct test_result r = {0, 0};
	const char *suite = argv[1];

	if (strcmp(suite, "spi") == 0) {
		run_spi(sh, &r);
	} else if (strcmp(suite, "i2c") == 0) {
		run_i2c(sh, &r);
	} else if (strcmp(suite, "gpio") == 0) {
		run_gpio(sh, &r);
#if defined(CONFIG_FFT_ACCEL)
	} else if (strcmp(suite, "fft") == 0) {
		run_fft(sh, &r);
#endif
	} else if (strcmp(suite, "all") == 0) {
		struct test_result rs = {0, 0}, ri = {0, 0}, rg = {0, 0};
		run_spi(sh, &rs);
		run_i2c(sh, &ri);
		run_gpio(sh, &rg);
#if defined(CONFIG_FFT_ACCEL)
		struct test_result rf = {0, 0};
		run_fft(sh, &rf);
		shell_print(sh,
			    "[TEST] spi: %d/%d  i2c: %d/%d  "
			    "gpio: %d/%d  fft: %d/%d",
			    rs.passed, rs.passed + rs.failed,
			    ri.passed, ri.passed + ri.failed,
			    rg.passed, rg.passed + rg.failed,
			    rf.passed, rf.passed + rf.failed);
#else
		shell_print(sh,
			    "[TEST] spi: %d/%d  i2c: %d/%d  gpio: %d/%d",
			    rs.passed, rs.passed + rs.failed,
			    ri.passed, ri.passed + ri.failed,
			    rg.passed, rg.passed + rg.failed);
#endif
	} else {
		shell_error(sh, "Unknown suite '%s'", suite);
		return -EINVAL;
	}
	return 0;
}

SHELL_STATIC_SUBCMD_SET_CREATE(test_sub,
	SHELL_CMD_ARG(run, NULL,
		      "run [spi|i2c|gpio|fft|all]  — run peripheral tests",
		      cmd_test_run, 2, 0),
	SHELL_SUBCMD_SET_END);

SHELL_CMD_REGISTER(test, &test_sub, "Peripheral test runner", NULL);
```
